VERSION ""

NS_ :

BS_:

BU_: RC27_18 EngineECU Display

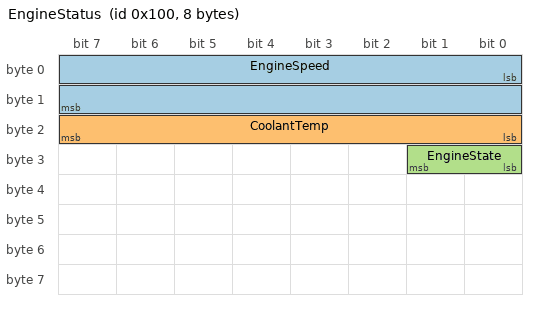
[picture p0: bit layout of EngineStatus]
BO_ 256 EngineStatus: 8 EngineECU
 SG_ EngineSpeed : 0|16@1+ (0.125,0) [0|8031.875] "rpm" RC27_18
 SG_ CoolantTemp : 16|8@1+ (1,-40) [-40|215] "degC" RC27_18
 SG_ EngineState : 24|2@1+ (1,0) [0|3] "" RC27_18

BO_ 512 VehicleCmd: 4 RC27_18
 SG_ PumpSetpoint : 0|16@1+ (0.1,0) [0|6553.5] "mA" Display
 SG_ EnableFlag : 16|1@1+ (1,0) [0|1] "" Display

BO_ 2566844673 ExtendedMsg: 8 EngineECU
 SG_ Torque : 0|16@1- (1,0) [-32768|32767] "Nm" RC27_18
